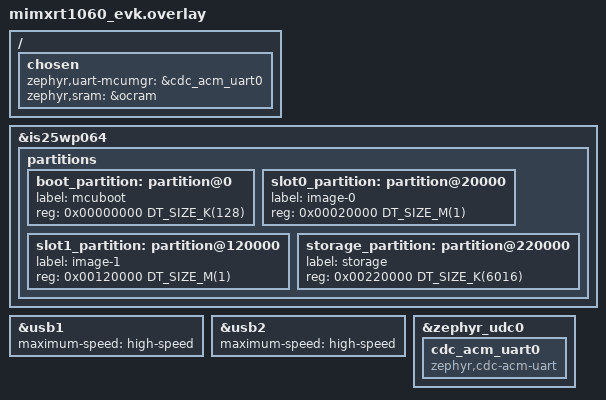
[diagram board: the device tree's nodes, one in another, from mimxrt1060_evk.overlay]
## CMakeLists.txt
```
# SPDX-License-Identifier: Apache-2.0

cmake_minimum_required(VERSION 3.20.0)

find_package(Zephyr REQUIRED HINTS $ENV{ZEPHYR_BASE})
project(hello_world)


target_include_directories(app
    PRIVATE ${CMAKE_SOURCE_DIR}/src/utils
            ${CMAKE_SOURCE_DIR}/src/managers
            ${CMAKE_SOURCE_DIR}/src/sensors
)

target_sources(app
    PRIVATE src/main.cpp
            src/sensors/imu_mock.cpp
            src/sensors/sensor_mock.cpp
            src/managers/imu_manager.cpp
            src/managers/sensor_manager.cpp
)
```

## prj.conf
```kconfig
CONFIG_SYSTEM_WORKQUEUE_STACK_SIZE=4096
CONFIG_MAIN_STACK_SIZE=4096

# C++ stuff
CONFIG_CPP=y
CONFIG_STD_CPP14=y
CONFIG_LIB_CPLUSPLUS=y

# Ensure an MCUboot-compatible binary is generated.
CONFIG_BOOTLOADER_MCUBOOT=y
CONFIG_MCUBOOT_SIGNATURE_KEY_FILE="zephyrproject/bootloader/mcuboot/root-rsa-2048.pem"

# Enable mcumgr.
CONFIG_MCUMGR=y
CONFIG_NET_BUF=y
CONFIG_ZCBOR=y
CONFIG_CRC=y
CONFIG_STREAM_FLASH=y
CONFIG_FLASH_MAP=y
CONFIG_UART_MCUMGR_RX_BUF_SIZE=256
CONFIG_UART_MCUMGR_RX_BUF_COUNT=5
CONFIG_MCUMGR_TRANSPORT_UART=y
CONFIG_BASE64=y

# Enable flash operations.
CONFIG_FLASH=y

# Enable most core commands.
CONFIG_IMG_MANAGER=y
CONFIG_MCUMGR_GRP_IMG=y

# USB Vendor
CONFIG_USB_DEVICE_PRODUCT="DEVICE"
CONFIG_USB_DEVICE_VID=0x246D
CONFIG_USB_DEVICE_PID=0x1050

# CDC
CONFIG_USB_DEVICE_STACK=y
CONFIG_SERIAL=y
CONFIG_UART_LINE_CTRL=y
CONFIG_USB_DEVICE_INITIALIZE_AT_BOOT=n
CONFIG_CONSOLE=y
# USB backend is serial device
CONFIG_MCUMGR_TRANSPORT_UART=y
CONFIG_BASE64=y

# Enable Nanopb
CONFIG_NANOPB=y

# Little FS
CONFIG_FLASH_MAP=y 
CONFIG_FLASH_PAGE_LAYOUT=y

CONFIG_FILE_SYSTEM=y
CONFIG_FILE_SYSTEM_LITTLEFS=y

CONFIG_MPU_ALLOW_FLASH_WRITE=y
```

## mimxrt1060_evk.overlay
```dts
/delete-node/ &boot_partition;
/delete-node/ &slot0_partition;
/delete-node/ &slot1_partition;
/delete-node/ &scratch_partition;
/delete-node/ &storage_partition;

&is25wp064 {
    partitions {
        boot_partition: partition@0 {
            label = "mcuboot";
            reg = <0x00000000 DT_SIZE_K(128)>;
        };
        slot0_partition: partition@20000 {
            label = "image-0";
            reg = <0x00020000 DT_SIZE_M(1)>;
        };
        slot1_partition: partition@120000 {
            label = "image-1";
            reg = <0x00120000 DT_SIZE_M(1)>;
        };
        storage_partition: partition@220000 {
            label = "storage";
            reg = <0x00220000 DT_SIZE_K(6016)>;
        };
    };
};

&usb1 {
    maximum-speed = "high-speed";
};

&usb2 {
    maximum-speed = "high-speed";
};

/ {
	chosen {
		zephyr,uart-mcumgr = &cdc_acm_uart0;
	};
};

&zephyr_udc0 {
	cdc_acm_uart0: cdc_acm_uart0 {
		compatible = "zephyr,cdc-acm-uart";
	};
};

// Use interal (OC) ram,  instead of external ram.
// This setting here replaces the default device tree "zephyr,sram" field in zephyrproject/zephyr/boards/arm/mimxrt1060_evk/mimxrt1060_evk.dts.
// The 'ocram' tag/label is defined in zephyrproject/zephyr/dts/arm/nxp/nxp_rt1060.dtsi.
/{
	chosen {
		zephyr,sram = &ocram;
	};
};
```

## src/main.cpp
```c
/*
 * Copyright (c) 2012-2014 Wind River Systems, Inc.
 *
 * SPDX-License-Identifier: Apache-2.0
 */

#include <zephyr/kernel.h>
#include <zephyr/usb/usb_device.h>

#include <zephyr/fs/fs.h>
#include <zephyr/fs/littlefs.h>

#include "imu_mock.h"
#include "sensor_mock.h"
#include "imu_manager.h"
#include "sensor_manager.h"

FS_LITTLEFS_DECLARE_DEFAULT_CONFIG(storage);
static struct fs_mount_t lfs_storage_mnt = {
	.type = FS_LITTLEFS,
	.mnt_point = "/lfs",
	.fs_data = &storage,
	.storage_dev = (void *)FIXED_PARTITION_ID(storage_partition),
};

int main(void)
{
	printk("Hello World! %s\n", CONFIG_BOARD);

	if (usb_enable(NULL) != 0) {
        printk("Failed to enable USB");
    }

    int rc;
    rc = fs_mount(&lfs_storage_mnt);
    if (rc < 0) {
        printk("Error mounting littlefs [%d]", rc);
    }

	// PRINT
	
	ImuMock imu_mock;
	ImuManager imu_mgr(imu_mock);

	SensorMock sen_mock;
	SensorManager sen_mgr(sen_mock);

	imu_mgr.AddSubscriber([](){printk("Got Imu Sample Data\n");});
	imu_mgr.Init();

	sen_mgr.AddSubscriber([](){printk("Got Sensor Sample Data\n");});
	sen_mgr.Init();

	while (1) {
        k_sleep(K_MSEC(1000));
	}
	return 0;
}
```
